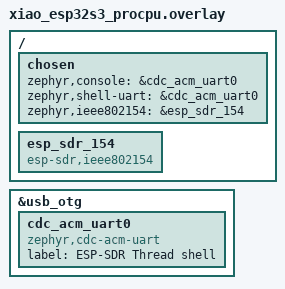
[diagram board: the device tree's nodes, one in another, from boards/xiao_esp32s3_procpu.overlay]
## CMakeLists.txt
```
# SPDX-License-Identifier: GPL-3.0-or-later

cmake_minimum_required(VERSION 3.20.0)

find_package(Zephyr REQUIRED HINTS $ENV{ZEPHYR_BASE})
project(thread)

# USB shell and DFU on the OTG port.
include(${CMAKE_CURRENT_LIST_DIR}/../common/common.cmake)

target_sources(app PRIVATE src/main.c)
```

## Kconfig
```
# SPDX-License-Identifier: GPL-3.0-or-later

mainmenu "thread: Thread end device on the esp-sdr 802.15.4 software radio"

# USB shell and DFU (common/), as the other apps.
rsource "../common/Kconfig"
source "samples/subsys/usb/common/Kconfig.sample_usbd"

source "Kconfig.zephyr"
```

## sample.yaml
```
sample:
  name: thread
  description: >-
    Thread end device (OpenThread MTD) on the esp-sdr 802.15.4 software radio
common:
  tags: esp-sdr
  sysbuild: true
  platform_allow:
    - xiao_esp32s3/esp32s3/procpu
  integration_platforms:
    - xiao_esp32s3/esp32s3/procpu
tests:
  sample.esp_sdr.thread:
    build_only: true
```

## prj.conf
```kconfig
CONFIG_NETWORKING=y
CONFIG_NET_IPV6=y
CONFIG_NET_IPV4=n
CONFIG_NET_UDP=y

# OpenThread: a minimal Thread device that joins an existing network from its
# dataset (`ot dataset set active <hex>`), started from the shell.
CONFIG_NET_L2_OPENTHREAD=y
CONFIG_OPENTHREAD_MTD=y
CONFIG_OPENTHREAD_MANUAL_START=y
CONFIG_OPENTHREAD_SHELL=y
# shortcut: settings in RAM, so the dataset is entered again after each boot;
# flash settings once the ring stops around their writes (doc/thread.md, M5).
CONFIG_OPENTHREAD_SETTINGS_RAM=y
# OpenThread's PSA keys (network key, PSKc) are persistent: the PSA ITS store
# on the settings subsystem in the storage partition. Written when a dataset is
# committed, from the shell or OpenThread thread (stacks in internal RAM).
CONFIG_FLASH=y
CONFIG_FLASH_MAP=y
CONFIG_ZMS=y
CONFIG_SETTINGS=y
CONFIG_SECURE_STORAGE_ITS_STORE_IMPLEMENTATION_SETTINGS=y

CONFIG_SHELL=y
CONFIG_NET_SHELL=y
CONFIG_LOG=y
CONFIG_LOG_MODE_DEFERRED=y
```

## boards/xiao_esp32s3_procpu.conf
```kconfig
# The esp-sdr software radio, as apps/wpan builds it. The Wi-Fi driver brings
# the radio up at boot; nothing may scan or connect.
CONFIG_WIFI=y
CONFIG_ESP32_WIFI_STA_POWER_SAVE_NONE=y
CONFIG_NET_L2_WIFI_SHELL=n

CONFIG_ESP_SDR=y
CONFIG_ESP_SDR_RX_DECIM=n
CONFIG_ESP_SDR_TX=y
CONFIG_ESP_SDR_TX_DAC=y
CONFIG_ESP_SDR_TX_DAC_HIGH_RAM=y
# Gapless receive: three dump banks, so the DRAM image ends below 0x3fcb0000.
CONFIG_ESP_SDR_RING=y
CONFIG_ESP_SDR_IEEE802154=y
CONFIG_IEEE802154=y
CONFIG_HWINFO=y

CONFIG_FPU=y
CONFIG_FPU_SHARING=y
CONFIG_SMP=y
CONFIG_SCHED_CPU_MASK=y

# Internal RAM is for the dump banks: the Wi-Fi heap and the network stacks
# and packet pools go to the octal PSRAM.
CONFIG_ESP_SPIRAM=y
CONFIG_SPIRAM_MODE_OCT=y
CONFIG_ESP_WIFI_HEAP_SPIRAM=y
CONFIG_ESP32_WIFI_NET_ALLOC_SPIRAM=y
CONFIG_ESP32_WIFI_STATIC_RX_BUFFER_NUM=2
CONFIG_ESP32_WIFI_AMPDU_RX_ENABLED=n
CONFIG_ESP32_WIFI_MGMT_SBUF_NUM=8
CONFIG_ESP32_WIFI_EVENT_TASK_STACK_SIZE=1024
CONFIG_NET_MGMT_EVENT_STACK_SIZE=1024
CONFIG_HEAP_MEM_POOL_IGNORE_MIN=y
# Peak 12216 bytes in apps/multiapp with these Wi-Fi buffers, nearly all the Wi-Fi driver's.
CONFIG_HEAP_MEM_POOL_SIZE=13312
CONFIG_SYS_HEAP_RUNTIME_STATS=y
# OpenThread's instance (about 19 KB of .bss) to PSRAM. Its thread stacks stay
# internal (libopenthread_utils.a): they write the flash (PSA ITS store).
CONFIG_ESP_SPIRAM_BSS_RELOC_LIBS_AND_OBJS="libopenthread-mtd.a"
# AES tables from flash, not 8 KB of .bss.
CONFIG_MBEDTLS_AES_ROM_TABLES=y

# Device and system init run on the main stack: settings, PSA crypto and
# OpenThread's instance overflow 1536 into the idle stacks below it. Peak 2576
# measured (with immediate logging).
CONFIG_MAIN_STACK_SIZE=3328
# Stacks at apps/multiapp's measured peaks (688, 528, 544, 640).
CONFIG_ESP32_TIMER_TASK_STACK_SIZE=896
CONFIG_UDC_DWC2_STACK_SIZE=704
CONFIG_LOG_PROCESS_THREAD_STACK_SIZE=704
CONFIG_USBD_CDC_ACM_STACK_SIZE=832
# Peak 512 per CPU.
CONFIG_ISR_STACK_SIZE=768
# Other stack sizes as apps/wpan measured them; the shell's is OpenThread's minimum.
CONFIG_IDLE_STACK_SIZE=512
CONFIG_SHELL_STACK_SIZE=3168
CONFIG_LOG_BUFFER_SIZE=448
CONFIG_SHELL_HISTORY=n

# USB device on the OTG port: shell on CDC-ACM, DFU with sysbuild/MCUboot.
CONFIG_USB_DEVICE_STACK_NEXT=y
CONFIG_SAMPLE_USBD_PRODUCT="ESP-SDR Thread"
CONFIG_SAMPLE_USBD_PID=0x0005
CONFIG_USBD_LOG_LEVEL_WRN=y
CONFIG_UDC_DRIVER_LOG_LEVEL_WRN=y
CONFIG_USBD_CDC_ACM_CLASS=y
# CDC-ACM carries the console and the shell: its own logging must stay off
# (usbd_cdc_acm.c's #warning is fatal under twister).
CONFIG_USBD_CDC_ACM_LOG_LEVEL_OFF=y
CONFIG_CDC_ACM_SERIAL_INITIALIZE_AT_BOOT=n
CONFIG_LOG_BACKEND_UART=n
CONFIG_USBD_CDC_ACM_WORKQUEUE=y
CONFIG_KERNEL_SHELL=y
CONFIG_SHELL_BACKEND_SERIAL_LOG_MESSAGE_QUEUE_SIZE=256

CONFIG_RESET_ON_FATAL_ERROR=y
CONFIG_APP_LIVENESS_WATCHDOG=y
```

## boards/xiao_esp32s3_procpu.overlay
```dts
/*
 * SPDX-License-Identifier: GPL-3.0-or-later
 */

/ {
	chosen {
		zephyr,console = &cdc_acm_uart0;
		zephyr,shell-uart = &cdc_acm_uart0;
		/* OpenThread's radio. */
		zephyr,ieee802154 = &esp_sdr_154;
	};

	esp_sdr_154: esp_sdr_154 {
		compatible = "esp-sdr,ieee802154";
		status = "okay";
	};
};

zephyr_udc0: &usb_otg {
	status = "okay";

	/* Console, shell and logs while OTG owns the USB port. */
	cdc_acm_uart0: cdc_acm_uart0 {
		compatible = "zephyr,cdc-acm-uart";
		label = "ESP-SDR Thread shell";
	};
};
```

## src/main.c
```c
/*
 * SPDX-License-Identifier: GPL-3.0-or-later
 *
 * Thread end device on the esp-sdr 802.15.4 software radio. OpenThread runs
 * the network and its shell (`ot ...`); this only brings up USB.
 */

#include <zephyr/app_version.h>
#include <zephyr/kernel.h>

#include "app_cpu.h"
#include "app_usb.h"

int main(void)
{
	printk("thread %s\n", APP_VERSION_STRING);
	/* Before USB starts: its controller interrupt lands on the CPU that allocates it. */
	app_cpu_pin_system_threads(0);
	if (app_usb_init() != 0) {
		printk("thread: usb init failed\n");
	}
	return 0;
}
```
